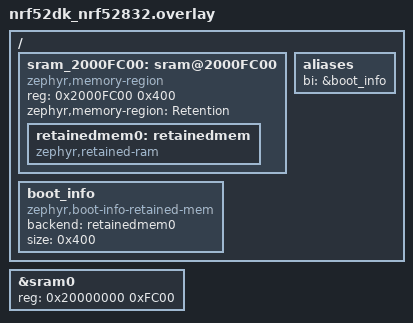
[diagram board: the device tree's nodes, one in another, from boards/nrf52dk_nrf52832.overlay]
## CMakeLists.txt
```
# Copyright (c) 2023 Laczen
# SPDX-License-Identifier: Apache-2.0

cmake_minimum_required(VERSION 3.20.0)

find_package(Zephyr REQUIRED HINTS $ENV{ZEPHYR_BASE})
project(boot_info_test)

target_sources(app PRIVATE src/main.c)
```

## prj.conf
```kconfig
# Copyright (c) 2023 Laczen
# SPDX-License-Identifier: Apache-2.0
CONFIG_BOOT_INFO=y
CONFIG_ZTEST=y
CONFIG_ZTEST_NEW_API=y
```

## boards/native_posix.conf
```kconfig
# Copyright (c) 2023 Laczen
# SPDX-License-Identifier: Apache-2.0
CONFIG_BBRAM=y
CONFIG_BBRAM_EMUL=y
```

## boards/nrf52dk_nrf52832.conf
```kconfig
# Copyright (c) 2023 Laczen
# SPDX-License-Identifier: Apache-2.0
CONFIG_MULTITHREADING=y
CONFIG_RETAINED_MEM=y
CONFIG_ZTEST_STACK_SIZE=8192
```

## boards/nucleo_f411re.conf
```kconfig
# Copyright (c) 2023 Laczen
# SPDX-License-Identifier: Apache-2.0
CONFIG_BBRAM=y
CONFIG_COUNTER=y
CONFIG_BBRAM_STM32=y
```

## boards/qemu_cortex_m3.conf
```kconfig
# Copyright (c) 2023 Laczen
# SPDX-License-Identifier: Apache-2.0
CONFIG_USERSPACE=y
```

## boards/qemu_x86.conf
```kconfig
# Copyright (c) 2023 Laczen
# SPDX-License-Identifier: Apache-2.0
CONFIG_ZTEST=y
CONFIG_ZTEST_NEW_API=y
CONFIG_ZTEST_STACK_SIZE=8192
CONFIG_EEPROM=y
CONFIG_EEPROM_SIMULATOR=y
```

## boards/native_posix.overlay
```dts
/*
 * Copyright (c) 2023 Laczen
 * SPDX-License-Identifier: Apache-2.0
 */

/ {
	bbram_emu: bbram_emu {
		compatible = "zephyr,bbram-emul";
		size = <0x20>;
        };

        boot_info: boot_info {
                compatible = "zephyr,boot-info-bbram";
                backend = <&bbram_emu>;
        };

        aliases {
                bi = &boot_info;
        };

};
```

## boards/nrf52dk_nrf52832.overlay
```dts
/*
 * Copyright (c) 2023 Laczen
 * SPDX-License-Identifier: Apache-2.0
 */

#include <common/mem.h>

/ {
	sram_2000FC00: sram@2000FC00 {
		compatible = "zephyr,memory-region", "mmio-sram";
		reg = <0x2000FC00 0x400>;
                zephyr,memory-region = "Retention";
                status = "okay";

		retainedmem0: retainedmem {
			compatible = "zephyr,retained-ram";
			status = "okay";
	        };
        };

        boot_info: boot_info {
                compatible = "zephyr,boot-info-retained-mem";
                backend = <&retainedmem0>;
                size = <0x400>;
        };

        aliases {
                bi = &boot_info;
        };

};

&sram0 {
	reg = <0x20000000 0xFC00>;
};
```

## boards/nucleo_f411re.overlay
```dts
/*
 * Copyright (c) 2023 Laczen
 * SPDX-License-Identifier: Apache-2.0
 */

&bbram {
        status = "okay";
};

/ {
        boot_info: boot_info {
                compatible = "zephyr,boot-info-bbram";
                backend = <&bbram>;
        };

        aliases {
                bi = &boot_info;
        };

};
```

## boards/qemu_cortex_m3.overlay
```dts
/*
 * Copyright (c) 2023 Laczen
 * SPDX-License-Identifier: Apache-2.0
 */

#include <common/mem.h>

/ {
	bi_region: sram@2000FFE0 {
		compatible = "zephyr,memory-region", "mmio-sram";
		reg = <0x2000FFE0 0x20>;
                zephyr,memory-region = "BI_REGION";
        };

        boot_info: boot_info {
                compatible = "zephyr,boot-info-ram";
                backend = <&bi_region>;
        };

        aliases {
                bi = &boot_info;
        };

};

&sram0 {
	reg = <0x20000000 0xFFE0>;
};
```

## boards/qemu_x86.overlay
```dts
/*
 * Copyright (c) 2023 Laczen
 * SPDX-License-Identifier: Apache-2.0
 */

/delete-node/ &storage_partition;

&flash_sim0 {

	partitions {
		compatible = "fixed-partitions";
		#address-cells = <1>;
		#size-cells = <1>;

		storage_partition: partition@1000 {
			label = "storage";
			reg = <0x00001000 0x00000400>;
		};
	};
};

/ {
        boot_info: boot_info {
                compatible = "zephyr,boot-info-flash";
                backend = <&storage_partition>;
        };

        aliases {
                bi = &boot_info;
        };

};
```

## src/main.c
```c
/*
 * Copyright (c) 2012-2014 Wind River Systems, Inc.
 * SPDX-License-Identifier: Apache-2.0
 */

#include <string.h>
#include <zephyr/kernel.h>
#include <zephyr/ztest.h>
#include <zephyr/devicetree.h>
#include <zephyr/sys/crc.h>
#include <zephyr/boot_info/boot_info.h>

#define BOOT_INFO DT_NODELABEL(boot_info)
#define BOOT_INFO_ALIAS DT_ALIAS(bi)

const uint8_t *hdr = "\x08\x04";

static void make_valid(uint8_t *data, size_t len)
{
	uint8_t crc8;

	memcpy(data, hdr, sizeof(hdr));
	crc8 = crc8_ccitt(0U, data, len - sizeof(crc8));
	memcpy(data + len - sizeof(crc8), &crc8, sizeof(crc8));
}

static bool is_valid(uint8_t *data, size_t len)
{
	if (memcmp(data, hdr, sizeof(hdr)) != 0) {
		return false;
	}

	uint8_t crc8 = crc8_ccitt(0U, data, len - sizeof(crc8));

	if (memcmp(data + len - sizeof(crc8), &crc8, sizeof(crc8)) != 0) {
		return false;
	}

	return true;
}

static void *boot_info_api_setup(void)
{
	if (IS_ENABLED(CONFIG_USERSPACE)) {
		k_object_access_grant(boot_info_get_device(BOOT_INFO),
				      k_current_get());
	}

	return NULL;
}

ZTEST_USER(boot_info_api, test_get_size)
{
	size_t bi_size = boot_info_get_size(BOOT_INFO);

	zassert_not_equal(bi_size, 0U, "Get size returned invalid value");
}

ZTEST_USER(boot_info_api, test_get_set)
{
	uint8_t wr[boot_info_get_size(BOOT_INFO)];
	uint8_t rd[boot_info_get_size(BOOT_INFO)];
	int rc = 0;

	memset(wr, 0, sizeof(wr));
	memset(rd, 0, sizeof(rd));

	rc = boot_info_get(BOOT_INFO, wr);
	zassert_equal(rc, 0, "boot_info_get returned [%d]", rc);

	memset(wr + sizeof(hdr), 0xa, sizeof(wr) - sizeof(hdr) - sizeof(uint32_t));
	make_valid(wr, sizeof(wr));

	rc = boot_info_set(BOOT_INFO, wr);
	zassert_equal(rc, 0, "boot_info_set returned [%d]", rc);

	rc = boot_info_get(BOOT_INFO, rd);
	zassert_equal(rc, 0, "boot_info_get returned [%d]", rc);

	zassert_equal(is_valid(rd, sizeof(rd)), true, "boot_info data is invalid");

	zassert_equal(memcmp(rd, wr, sizeof(wr)), 0, "data mismatch");
}

ZTEST_SUITE(boot_info_api, NULL, boot_info_api_setup, NULL, NULL, NULL);
```
